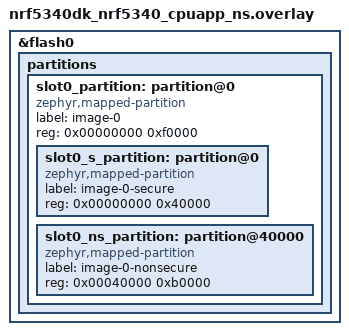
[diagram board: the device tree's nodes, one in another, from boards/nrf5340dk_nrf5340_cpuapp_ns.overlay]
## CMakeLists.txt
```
#
# Copyright (c) 2019 Nordic Semiconductor ASA
#
# SPDX-License-Identifier: LicenseRef-Nordic-5-Clause
#
cmake_minimum_required(VERSION 3.20.0)

find_package(Zephyr REQUIRED HINTS $ENV{ZEPHYR_BASE})
project(NONE)

FILE(GLOB app_sources src/*.c)
# NORDIC SDK APP START
target_sources(app PRIVATE ${app_sources})
# NORDIC SDK APP END

zephyr_library_include_directories(${ZEPHYR_BASE}/samples/bluetooth)
```

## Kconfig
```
#
# Copyright (c) 2018 Nordic Semiconductor
#
# SPDX-License-Identifier: LicenseRef-Nordic-5-Clause
#

menu "Nordic BLE HIDS Keyboard sample"

config SAMPLE_NFC_OOB_PAIRING
	bool "Enable NFC OOB pairing"
	depends on HAS_HW_NRF_NFCT
	default y
	select NFC_T2T_NRFXLIB
	select NFC_NDEF
	select NFC_NDEF_MSG
	select NFC_NDEF_RECORD
	select NFC_NDEF_LE_OOB_REC

config SETTINGS
	default y

config ZMS
	default y if (SOC_FLASH_NRF_RRAM || SOC_FLASH_NRF_MRAM)

config NVS
	default y if !(SOC_FLASH_NRF_RRAM || SOC_FLASH_NRF_MRAM)

endmenu

source "Kconfig.zephyr"
```

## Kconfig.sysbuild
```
#
# Copyright (c) 2023 Nordic Semiconductor
#
# SPDX-License-Identifier: LicenseRef-Nordic-5-Clause
#

config NRF_DEFAULT_IPC_RADIO
	default y

source "share/sysbuild/Kconfig"
```

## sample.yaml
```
sample:
  description: Bluetooth Low Energy Human Interface Device keyboard sample
  name: Bluetooth LE HIDS keyboard
common:
  sysbuild: true
  harness_config:
    type: multi_line
    ordered: true
    regex:
      - "Starting Bluetooth Peripheral HIDS keyboard sample"
      - "Bluetooth initialized"
  timeout: 15
  tags:
    - bluetooth
    - ci_build
    - sysbuild
    - ci_samples_bluetooth
tests:
  sample.bluetooth.peripheral_hids_keyboard:
    harness: console
    integration_platforms:
      - nrf5340dk/nrf5340/cpuapp/ns
      - nrf54h20dk/nrf54h20/cpuapp
      - nrf54l15dk/nrf54l05/cpuapp
      - nrf54lm20dk/nrf54lm20a/cpuapp
      - nrf54lm20dk/nrf54lm20b/cpuapp
      - nrf54ls05dk/nrf54ls05a/cpuapp
      - nrf54lc10dk/nrf54lc10a/cpuapp
    platform_allow:
      - nrf5340dk/nrf5340/cpuapp
      - nrf5340dk/nrf5340/cpuapp/ns
      - nrf54l15dk/nrf54l05/cpuapp
      - nrf54l15dk/nrf54l10/cpuapp
      - nrf54l15dk/nrf54l15/cpuapp
      - nrf54lm20dk/nrf54lm20a/cpuapp
      - nrf54lm20dk/nrf54lm20b/cpuapp
      - nrf54ls05dk/nrf54ls05a/cpuapp
      - nrf54ls05dk/nrf54ls05b/cpuapp
      - nrf54lc10dk/nrf54lc10a/cpuapp
      - nrf54lc10dk/nrf54lc10a/cpuapp/ns
      - nrf54h20dk/nrf54h20/cpuapp
  sample.bluetooth.peripheral_hids_keyboard.hid_sci:
    harness: console
    extra_args: FILE_SUFFIX=hid_sci
    integration_platforms:
      - nrf54l15dk/nrf54l05/cpuapp
      - nrf54lm20dk/nrf54lm20a/cpuapp
      - nrf54lm20dk/nrf54lm20b/cpuapp
      - nrf54ls05dk/nrf54ls05a/cpuapp
      - nrf54lc10dk/nrf54lc10a/cpuapp
    platform_allow:
      - nrf54l15dk/nrf54l05/cpuapp
      - nrf54lm20dk/nrf54lm20a/cpuapp
      - nrf54lm20dk/nrf54lm20b/cpuapp
      - nrf54ls05dk/nrf54ls05a/cpuapp
      - nrf54ls05dk/nrf54ls05b/cpuapp
      - nrf54lc10dk/nrf54lc10a/cpuapp
```

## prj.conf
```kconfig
#
# Copyright (c) 2019-2025 Nordic Semiconductor ASA
#
# SPDX-License-Identifier: LicenseRef-Nordic-5-Clause
#
CONFIG_NCS_SAMPLES_DEFAULTS=y

CONFIG_BT=y
CONFIG_BT_MAX_CONN=2
CONFIG_BT_MAX_PAIRED=2
CONFIG_BT_SMP=y
CONFIG_BT_ATT_TX_COUNT=5
CONFIG_BT_PERIPHERAL=y
CONFIG_BT_DEVICE_NAME="Nordic_HIDS_keyboard"
CONFIG_BT_DEVICE_APPEARANCE=961

# Disable automatic initiation of PHY updates and the SMP Security Requests.
# Workaround to prevent disconnection with the following disconnect reasons:
# - 0x08 (BT_HCI_ERR_CONN_TIMEOUT)
# - 0x13 (BT_HCI_ERR_REMOTE_USER_TERM_CONN)
# - 0x23 (BT_HCI_ERR_LL_PROC_COLLISION)
# - 0x2A (BT_HCI_ERR_DIFF_TRANS_COLLISION)
# Some laptop Bluetooth controllers may simultaneously trigger two Link Layer
# procedures which results in a procedure collision and disconnection.
CONFIG_BT_GATT_AUTO_SEC_REQ=n
CONFIG_BT_AUTO_PHY_PERIPHERAL_NONE=y

CONFIG_BT_BAS=y
CONFIG_BT_HIDS=y
CONFIG_BT_HIDS_INPUT_REP_MAX=1
CONFIG_BT_HIDS_OUTPUT_REP_MAX=1
CONFIG_BT_HIDS_FEATURE_REP_MAX=0
CONFIG_BT_HIDS_ATTR_MAX=21
CONFIG_BT_HIDS_MAX_CLIENT_COUNT=2
CONFIG_BT_HIDS_DEFAULT_PERM_RW_ENCRYPT=y
CONFIG_BT_GATT_UUID16_POOL_SIZE=40
CONFIG_BT_GATT_CHRC_POOL_SIZE=20

CONFIG_BT_CONN_CTX=y

CONFIG_BT_DIS=y
CONFIG_BT_DIS_MANUF_NAME=y
CONFIG_BT_DIS_MANUF_NAME_STR="NordicSemiconductor"
CONFIG_BT_DIS_PNP=y
CONFIG_BT_DIS_PNP_VID_SRC=2
CONFIG_BT_DIS_PNP_VID=0x1915
CONFIG_BT_DIS_PNP_PID=0xEEEF
CONFIG_BT_DIS_PNP_VER=0x0100

CONFIG_MAIN_STACK_SIZE=2048
CONFIG_SYSTEM_WORKQUEUE_STACK_SIZE=2048

CONFIG_BT_SETTINGS=y
CONFIG_FLASH=y
CONFIG_FLASH_PAGE_LAYOUT=y
CONFIG_FLASH_MAP=y

CONFIG_DK_LIBRARY=y
```

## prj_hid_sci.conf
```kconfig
#
# Copyright (c) 2026 Nordic Semiconductor ASA
#
# SPDX-License-Identifier: LicenseRef-Nordic-5-Clause
#
CONFIG_NCS_SAMPLES_DEFAULTS=y

CONFIG_BT=y
CONFIG_BT_MAX_CONN=1
CONFIG_BT_MAX_PAIRED=1
CONFIG_BT_SMP=y
CONFIG_BT_ATT_TX_COUNT=5
CONFIG_BT_PERIPHERAL=y
CONFIG_BT_DEVICE_NAME="Nordic_HIDS_keyboard"
CONFIG_BT_DEVICE_APPEARANCE=961

# Disable automatic initiation of PHY updates and the SMP Security Requests.
# Workaround to prevent disconnection with the following disconnect reasons:
# - 0x08 (BT_HCI_ERR_CONN_TIMEOUT)
# - 0x13 (BT_HCI_ERR_REMOTE_USER_TERM_CONN)
# - 0x23 (BT_HCI_ERR_LL_PROC_COLLISION)
# - 0x2A (BT_HCI_ERR_DIFF_TRANS_COLLISION)
# Some laptop Bluetooth controllers may simultaneously trigger two Link Layer
# procedures which results in a procedure collision and disconnection.
CONFIG_BT_GATT_AUTO_SEC_REQ=n
CONFIG_BT_AUTO_PHY_PERIPHERAL_NONE=y

CONFIG_BT_BAS=y
CONFIG_BT_HIDS=y
CONFIG_BT_HIDS_INPUT_REP_MAX=1
CONFIG_BT_HIDS_OUTPUT_REP_MAX=1
CONFIG_BT_HIDS_FEATURE_REP_MAX=0
CONFIG_BT_HIDS_MAX_CLIENT_COUNT=1
CONFIG_BT_HIDS_DEFAULT_PERM_RW_ENCRYPT=y
CONFIG_BT_GATT_UUID16_POOL_SIZE=40
CONFIG_BT_GATT_CHRC_POOL_SIZE=20

CONFIG_BT_CONN_CTX=y

CONFIG_BT_DIS=y
CONFIG_BT_DIS_MANUF_NAME=y
CONFIG_BT_DIS_MANUF_NAME_STR="NordicSemiconductor"
CONFIG_BT_DIS_PNP=y
CONFIG_BT_DIS_PNP_VID_SRC=2
CONFIG_BT_DIS_PNP_VID=0x1915
CONFIG_BT_DIS_PNP_PID=0xEEEF
CONFIG_BT_DIS_PNP_VER=0x0100

CONFIG_MAIN_STACK_SIZE=2048
CONFIG_SYSTEM_WORKQUEUE_STACK_SIZE=2048

CONFIG_BT_SETTINGS=y
CONFIG_FLASH=y
CONFIG_FLASH_PAGE_LAYOUT=y
CONFIG_FLASH_MAP=y

CONFIG_DK_LIBRARY=y

# HID SCI configuration
CONFIG_BT_HIDS_ATTR_MAX=30

CONFIG_BT_GAP_PERIPHERAL_PREF_PARAMS=n

CONFIG_BT_SUBRATING=y
CONFIG_BT_LE_EXTENDED_FEAT_SET=y

CONFIG_BT_SHORTER_CONNECTION_INTERVALS=y

CONFIG_BT_HIDS_SCI=y

# Optimize for best possible performance in HID SCI FAST mode

# 875 us minimum connection interval
CONFIG_BT_HIDS_SCI_FAST_INTERVAL_MIN_125US=7
CONFIG_BT_HIDS_SCI_FULL_RANGE_INTERVAL_MIN_125US=7

# Keep the maximum connection event below the minimum connection interval of 875 us
# Without this, the effective minimum connection interval would be 1125 us.
CONFIG_BT_CTLR_SDC_MAX_CONN_EVENT_LEN_DEFAULT=750

# Frame space update is required to achieve the lowest connection intervals.
CONFIG_BT_FRAME_SPACE_UPDATE=y
```

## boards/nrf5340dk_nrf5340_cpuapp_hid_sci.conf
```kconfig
#
# Copyright (c) 2026 Nordic Semiconductor ASA
#
# SPDX-License-Identifier: LicenseRef-Nordic-5-Clause
#

# The radio notification connection callbacks are not available
# from the nRF5340 application core.
CONFIG_BT_RADIO_NOTIFICATION_CONN_CB=n

# 1000 us minimum connection interval - local controller minimum for nRF5340
CONFIG_BT_HIDS_SCI_FAST_INTERVAL_MIN_125US=8
CONFIG_BT_HIDS_SCI_FULL_RANGE_INTERVAL_MIN_125US=8
```

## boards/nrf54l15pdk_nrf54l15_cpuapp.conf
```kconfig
#
# Copyright (c) 2024 Nordic Semiconductor
#
# SPDX-License-Identifier: LicenseRef-Nordic-5-Clause
#

# Workaround:
# The nRF54L15 PDK (PCA10156) revisions v0.2.0 AA0-ES2, v0.2.0 AA0-ES3,
# and v0.2.1 AB0-ES5 have Buttons 3 and 4 connected to the GPIO port
# which does not support interrupts.
CONFIG_DK_LIBRARY_BUTTON_NO_ISR=y
```

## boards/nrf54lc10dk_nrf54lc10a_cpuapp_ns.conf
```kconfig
#
# Copyright (c) 2026 Nordic Semiconductor ASA
#
# SPDX-License-Identifier: LicenseRef-Nordic-5-Clause
#

CONFIG_MAIN_STACK_SIZE=3584
```

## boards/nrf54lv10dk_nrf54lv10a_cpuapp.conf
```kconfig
#
# Copyright (c) 2025 Nordic Semiconductor ASA
#
# SPDX-License-Identifier: LicenseRef-Nordic-5-Clause
#

CONFIG_MAIN_STACK_SIZE=3584

# Workaround for issue NCSDK-33313

# Disable Cracken for all but RNG, and switch to software crypto.

CONFIG_PSA_CRYPTO_DRIVER_OBERON=y
CONFIG_PSA_CRYPTO_DRIVER_CRACEN=y

CONFIG_PSA_USE_CRACEN_CIPHER_DRIVER=n
CONFIG_PSA_USE_CRACEN_AEAD_DRIVER=n
CONFIG_PSA_USE_CRACEN_HASH_DRIVER=n
CONFIG_PSA_USE_CRACEN_MAC_DRIVER=n
CONFIG_PSA_USE_CRACEN_KEY_AGREEMENT_DRIVER=n
CONFIG_PSA_USE_CRACEN_ASYMMETRIC_DRIVER=n
CONFIG_PSA_USE_CRACEN_KEY_MANAGEMENT_DRIVER=n
CONFIG_PSA_USE_CRACEN_KEY_DERIVATION_DRIVER=n
CONFIG_PSA_USE_CRACEN_PAKE_DRIVER=n
CONFIG_PSA_USE_CRACEN_ASYMMETRIC_SIGNATURE_DRIVER=n

# END of Workaround for issue NCSDK-33313

CONFIG_NFC_OOB_PAIRING=n
```

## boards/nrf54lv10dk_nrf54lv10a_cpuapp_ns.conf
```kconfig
#
# Copyright (c) 2025 Nordic Semiconductor ASA
#
# SPDX-License-Identifier: LicenseRef-Nordic-5-Clause
#

CONFIG_MAIN_STACK_SIZE=3584
```

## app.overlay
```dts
/*
 * Copyright (c) 2025 Nordic Semiconductor ASA
 *
 * SPDX-License-Identifier: LicenseRef-Nordic-5-Clause
 */

&nfct {
	status = "okay";
};
```

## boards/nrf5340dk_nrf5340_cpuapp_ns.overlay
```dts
/*
 * Copyright (c) 2026 Nordic Semiconductor ASA
 *
 * SPDX-License-Identifier: LicenseRef-Nordic-5-Clause
 */

/*
 * No bootloader is built in this configuration.
 * The default nRF5340 partition layout reserves the first 64 KB for MCUboot.
 * The TF-M storage and settings partitions from the board devicetree
 * (0xf0000 onwards) are kept and still used.
 */
/delete-node/ &boot_partition;
/delete-node/ &slot0_partition;
/delete-node/ &slot1_partition;

&flash0 {
	partitions {
		slot0_partition: partition@0 {
			compatible = "zephyr,mapped-partition";
			label = "image-0";
			reg = <0x00000000 0xf0000>;
			ranges = <0x0 0x0 0xf0000>;
			#address-cells = <1>;
			#size-cells = <1>;

			slot0_s_partition: partition@0 {
				compatible = "zephyr,mapped-partition";
				label = "image-0-secure";
				reg = <0x00000000 0x40000>;
			};

			slot0_ns_partition: partition@40000 {
				compatible = "zephyr,mapped-partition";
				label = "image-0-nonsecure";
				reg = <0x00040000 0xb0000>;
			};
		};
	};
};
```

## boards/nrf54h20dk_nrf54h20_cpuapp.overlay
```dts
/*
 * Copyright (c) 2025 Nordic Semiconductor ASA
 *
 * SPDX-License-Identifier: LicenseRef-Nordic-5-Clause
 */

&nfct {
	status = "okay";
	memory-regions = <&cpuapp_dma_region>;
};
```

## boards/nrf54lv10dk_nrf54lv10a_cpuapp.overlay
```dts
/*
 * Copyright (c) 2025 Nordic Semiconductor ASA
 *
 * SPDX-License-Identifier: LicenseRef-Nordic-5-Clause
 */

/ {
	/delete-node/ nfct;
};
```

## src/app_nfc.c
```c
/*
 * Copyright (c) 2019 Nordic Semiconductor ASA
 *
 * SPDX-License-Identifier: LicenseRef-Nordic-5-Clause
 */

#if CONFIG_SAMPLE_NFC_OOB_PAIRING

#include "app_nfc.h"
#include <nfc_t2t_lib.h>

static struct bt_le_oob oob_local;
static uint8_t ndef_msg_buf[256]; /* Buffer used to hold an NFC NDEF message. */

void nfc_field_detected(void);
void nfc_field_lost(void);

static void nfc_callback(void *context,
			 nfc_t2t_event_t event,
			 const uint8_t *data,
			 size_t data_length)
{
	ARG_UNUSED(context);
	ARG_UNUSED(data);
	ARG_UNUSED(data_length);

	switch (event) {
	case NFC_T2T_EVENT_FIELD_ON:
		nfc_field_detected();
		break;
	case NFC_T2T_EVENT_FIELD_OFF:
		nfc_field_lost();
		break;
	default:
		break;
	}
}

int nfc_ndef_le_oob_msg_encode(uint8_t *buffer, uint32_t *len)
{
	int err;
	struct nfc_ndef_le_oob_rec_payload_desc rec_payload;

	err = bt_le_oob_get_local(BT_ID_DEFAULT, &oob_local);
	if (err) {
		printk("Error while fetching local OOB data: %d\n", err);
	}

	memset(&rec_payload, 0, sizeof(rec_payload));

	rec_payload.addr = &oob_local.addr;
	rec_payload.le_sc_data = &oob_local.le_sc_data;
	rec_payload.local_name = bt_get_name();
	rec_payload.le_role = NFC_NDEF_LE_OOB_REC_LE_ROLE(
		NFC_NDEF_LE_OOB_REC_LE_ROLE_PERIPH_ONLY);
	rec_payload.appearance = NFC_NDEF_LE_OOB_REC_APPEARANCE(
		CONFIG_BT_DEVICE_APPEARANCE);
	rec_payload.flags = NFC_NDEF_LE_OOB_REC_FLAGS(BT_LE_AD_NO_BREDR);

	/* Create NFC NDEF message description, capacity - 1 record */
	NFC_NDEF_MSG_DEF(nfc_le_oob_msg, 1);

	/* Create NFC NDEF LE OOB Record description without record ID field */
	NFC_NDEF_LE_OOB_RECORD_DESC_DEF(nfc_le_oob_rec, 0, &rec_payload);

	/* Add LE OOB Record as lone record to message */
	err = nfc_ndef_msg_record_add(&NFC_NDEF_MSG(nfc_le_oob_msg),
			&NFC_NDEF_LE_OOB_RECORD_DESC(nfc_le_oob_rec));
	if (err < 0) {
		printk("Error while adding LE OOB record: %d\n", err);
		return err;
	}

	err = nfc_ndef_msg_encode(&NFC_NDEF_MSG(nfc_le_oob_msg),
				      buffer,
				      len);
	if (err < 0) {
		printk("Error during NDEF message encoding: %d\n", err);
		return err;
	}

	return 0;
}

void app_nfc_init(void)
{
	uint32_t len = sizeof(ndef_msg_buf);

	printk("NFC configuration start\n");

	/* Set up NFC */
	if (nfc_t2t_setup(nfc_callback, NULL) < 0) {
		printk("Cannot setup NFC T2T library!\n");
	}

	/* Prepare an NDEF message with LE OOB record. */
	if (nfc_ndef_le_oob_msg_encode(ndef_msg_buf, &len) < 0) {
		printk("Cannot encode BLE pair message!\n");
	}

	/* Set created message as the NFC payload */
	if (nfc_t2t_payload_set(ndef_msg_buf, len) < 0) {
		printk("Cannot set payload!\n");
	}

	/* Start sensing NFC field */
	if (nfc_t2t_emulation_start() < 0) {
		printk("Cannot start emulation!\n");
	}

	printk("NFC configuration done\n");
}

struct bt_le_oob *app_nfc_oob_data_get(void)
{
	return &oob_local;
}

#endif /* CONFIG_SAMPLE_NFC_OOB_PAIRING */
```

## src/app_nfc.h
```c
/*
 * Copyright (c) 2019 Nordic Semiconductor ASA
 *
 * SPDX-License-Identifier: LicenseRef-Nordic-5-Clause
 */

#include <nfc/ndef/msg.h>
#include <nfc/ndef/uri_msg.h>
#include <nfc/ndef/le_oob_rec.h>

/** @brief Initialize NFC.
 */
void app_nfc_init(void);

/** @brief Retrieve Out of Band data.
 */
struct bt_le_oob *app_nfc_oob_data_get(void);
```
